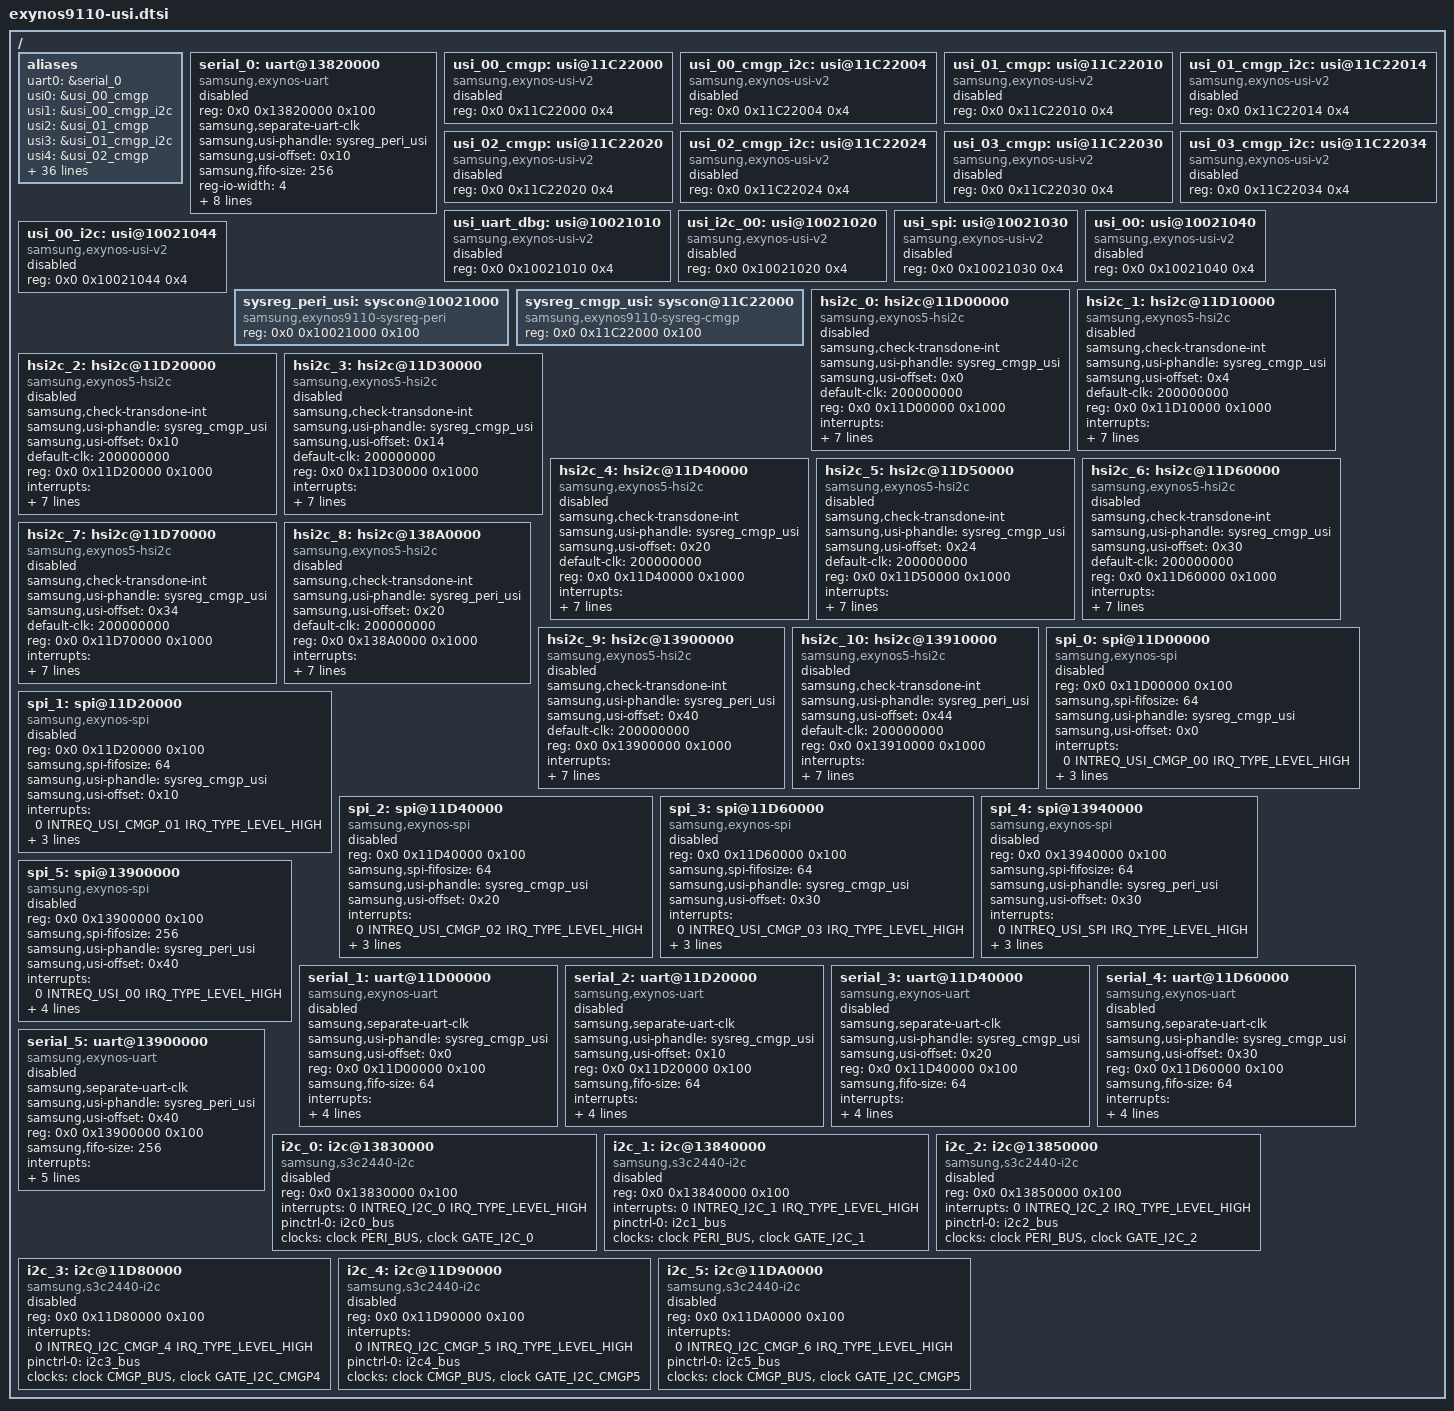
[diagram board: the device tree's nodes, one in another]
/*
 * Samsung's Exynos9110 SoC USI device tree source
 *
 * Copyright (c) 2020 Samsung Electronics Co., Ltd.
 *		http://www.samsung.com
 *
 * Samsung's Exynos9110 SoC USI channels are listed as device
 * tree nodes are listed in this file.
 *
 * This program is free software; you can redistribute it and/or modify
 * it under the terms of the GNU General Public License version 2 as
 * published by the Free Software Foundation.
*/

/ {
	aliases {
		uart0 = &serial_0;
		usi0 = &usi_00_cmgp;
		usi1 = &usi_00_cmgp_i2c;
		usi2 = &usi_01_cmgp;
		usi3 = &usi_01_cmgp_i2c;
		usi4 = &usi_02_cmgp;
		usi5 = &usi_02_cmgp_i2c;
		usi6 = &usi_03_cmgp;
		usi7 = &usi_03_cmgp_i2c;
		usi8 = &usi_uart_dbg;
		usi9 = &usi_i2c_00;
		usi10 = &usi_spi;
		usi11 = &usi_00;
		usi12 = &usi_00_i2c;
		hsi2c0 = &hsi2c_0;
		hsi2c1 = &hsi2c_1;
		hsi2c2 = &hsi2c_2;
		hsi2c3 = &hsi2c_3;
		hsi2c4 = &hsi2c_4;
		hsi2c5 = &hsi2c_5;
		hsi2c6 = &hsi2c_6;
		hsi2c7 = &hsi2c_7;
		hsi2c8 = &hsi2c_8;
		hsi2c9 = &hsi2c_9;
		hsi2c10 = &hsi2c_10;
		spi0 = &spi_0;
		spi1 = &spi_1;
		spi2 = &spi_2;
		spi3 = &spi_3;
		spi4 = &spi_4;
		spi5 = &spi_5;
		uart1 = &serial_1;
		uart2 = &serial_2;
		uart3 = &serial_3;
		uart4 = &serial_4;
		uart5 = &serial_5;
		i2c0 = &i2c_0;
		i2c1 = &i2c_1;
		i2c2 = &i2c_2;
		i2c3 = &i2c_3;
		i2c4 = &i2c_4;
		i2c5 = &i2c_5;
	};

	serial_0: uart@13820000 {
		compatible = "samsung,exynos-uart";
		reg = <0x0 0x13820000 0x100>;
		samsung,separate-uart-clk;
		samsung,usi-phandle = <&sysreg_peri_usi>;
		samsung,usi-offset = <0x10>;
		samsung,fifo-size = <256>;
		reg-io-width = <4>;
		interrupts = <0 INTREQ_USI_UART IRQ_TYPE_LEVEL_HIGH>;
		pinctrl-names = "default";
		pinctrl-0 = <&uart0_bus_single>; /* or _bus_dual */
		clocks = <&clock GATE_USI_UART>, <&clock PERI_UART>;
		clock-names = "gate_uart_clk0", "ipclk_uart0";
		samsung,usi-serial-v2;
		samsung,dbg-uart-ch;
		samsung,dbg-uart-baud = <115200>;
		samsung,dbg-word-len = <8>;
		status = "disabled";
	};

	/* USI_00_CMGP */
	usi_00_cmgp: usi@11C22000 {
		compatible = "samsung,exynos-usi-v2";
		reg = <0x0 0x11C22000 0x4>;
		/*	usi_mode_v2 = "i2c" or "spi" or "uart"	*/
		status = "disabled";
	};

	/* USI_00_CMGP_I2C */
	usi_00_cmgp_i2c: usi@11C22004 {
		compatible = "samsung,exynos-usi-v2";
		reg = <0x0 0x11C22004 0x4>;
		/*	usi_mode_v2 = "i2c" */
		status = "disabled";
	};

	/* USI_01_CMGP */
	usi_01_cmgp: usi@11C22010 {
		compatible = "samsung,exynos-usi-v2";
		reg = <0x0 0x11C22010 0x4>;
		/*	usi_mode_v2 = "i2c" or "spi" or "uart"	*/
		status = "disabled";
	};

	/* USI_01_CMGP_I2C */
	usi_01_cmgp_i2c: usi@11C22014 {
		compatible = "samsung,exynos-usi-v2";
		reg = <0x0 0x11C22014 0x4>;
		/*	usi_mode_v2 = "i2c" */
		status = "disabled";
	};

	/* USI_02_CMGP */
	usi_02_cmgp: usi@11C22020 {
		compatible = "samsung,exynos-usi-v2";
		reg = <0x0 0x11C22020 0x4>;
		/*	usi_mode_v2 = "i2c" or "spi" or "uart"	*/
		status = "disabled";
	};

	/* USI_02_CMGP_I2C */
	usi_02_cmgp_i2c: usi@11C22024 {
		compatible = "samsung,exynos-usi-v2";
		reg = <0x0 0x11C22024 0x4>;
		/*	usi_mode_v2 = "i2c" */
		status = "disabled";
	};

	/* USI_03_CMGP */
	usi_03_cmgp: usi@11C22030 {
		compatible = "samsung,exynos-usi-v2";
		reg = <0x0 0x11C22030 0x4>;
		/*	usi_mode_v2 = "i2c" or "spi" or "uart"	*/
		status = "disabled";
	};

	/* USI_03_CMGP_I2C */
	usi_03_cmgp_i2c: usi@11C22034 {
		compatible = "samsung,exynos-usi-v2";
		reg = <0x0 0x11C22034 0x4>;
		/*	usi_mode_v2 = "i2c" */
		status = "disabled";
	};

	/* USI_UART_DBG */
	usi_uart_dbg: usi@10021010 {
		compatible = "samsung,exynos-usi-v2";
		reg = <0x0 0x10021010 0x4>;
		/*	usi_mode_v2 = "i2c" */
		status = "disabled";
	};

	/* USI_I2C_00 */
	usi_i2c_00: usi@10021020 {
		compatible = "samsung,exynos-usi-v2";
		reg = <0x0 0x10021020 0x4>;
		/*	usi_mode_v2 = "i2c" */
		status = "disabled";
	};

	/* USI_SPI */
	usi_spi: usi@10021030 {
		compatible = "samsung,exynos-usi-v2";
		reg = <0x0 0x10021030 0x4>;
		/*	usi_mode_v2 = "i2c" */
		status = "disabled";
	};

	/* USI_00 */
	usi_00: usi@10021040 {
		compatible = "samsung,exynos-usi-v2";
		reg = <0x0 0x10021040 0x4>;
		/*	usi_mode_v2 = "i2c" */
		status = "disabled";
	};

	/* USI_00_I2C */
	usi_00_i2c: usi@10021044 {
		compatible = "samsung,exynos-usi-v2";
		reg = <0x0 0x10021044 0x4>;
		/*	usi_mode_v2 = "i2c" */
		status = "disabled";
	};

	/* USI_SW_CONF for PERI USI*/
	sysreg_peri_usi: syscon@10021000 {
		compatible = "samsung,exynos9110-sysreg-peri", "syscon";
		reg = <0x0 0x10021000 0x100>;
	};

	/* USI_SW_CONF for CMGP USI*/
	sysreg_cmgp_usi: syscon@11C22000 {
		compatible = "samsung,exynos9110-sysreg-cmgp", "syscon";
		reg = <0x0 0x11C22000 0x100>;
	};

	/* USI_00_CMGP */
	hsi2c_0: hsi2c@11D00000 {
		compatible = "samsung,exynos5-hsi2c";
		samsung,check-transdone-int;
		samsung,usi-phandle = <&sysreg_cmgp_usi>;
		samsung,usi-offset = <0x0>;
		default-clk = <200000000>;
		reg = <0x0 0x11D00000 0x1000>;
		interrupts = <0 INTREQ_USI_CMGP_00 IRQ_TYPE_LEVEL_HIGH>;
		#address-cells = <1>;
		#size-cells = <0>;
		pinctrl-names = "default";
		pinctrl-0 = <&hsi2c0_bus>;
		clocks = <&clock CMGP_USI0>, <&clock GATE_USI_CMGP0>;
		clock-names = "ipclk_hsi2c", "gate_hsi2c_clk";
		samsung,scl-clk-stretching;
		samsung,usi-i2c-v2;
		gpio_scl= <&gpm0 0 0x1>;
		gpio_sda= <&gpm1 0 0x1>;
		status = "disabled";
	};

	/* USI_00_CMGP_I2C */
	hsi2c_1: hsi2c@11D10000 {
		compatible = "samsung,exynos5-hsi2c";
		samsung,check-transdone-int;
		samsung,usi-phandle = <&sysreg_cmgp_usi>;
		samsung,usi-offset = <0x4>;
		default-clk = <200000000>;
		reg = <0x0 0x11D10000 0x1000>;
		interrupts = <0 INTREQ_USI_CMGP_00_I2C IRQ_TYPE_LEVEL_HIGH>;
		#address-cells = <1>;
		#size-cells = <0>;
		pinctrl-names = "default";
		pinctrl-0 = <&hsi2c1_bus>;
		clocks = <&clock CMGP_I2C0>, <&clock GATE_I2C_CMGP0>;
		clock-names = "ipclk_hsi2c", "gate_hsi2c_clk";
		samsung,scl-clk-stretching;
		samsung,usi-i2c-v2;
		gpio_scl= <&gpm2 0 0x1>;
		gpio_sda= <&gpm3 0 0x1>;
		status = "disabled";
	};

	/* USI_01_CMGP */
	hsi2c_2: hsi2c@11D20000 {
		compatible = "samsung,exynos5-hsi2c";
		samsung,check-transdone-int;
		samsung,usi-phandle = <&sysreg_cmgp_usi>;
		samsung,usi-offset = <0x10>;
		default-clk = <200000000>;
		reg = <0x0 0x11D20000 0x1000>;
		interrupts = <0 INTREQ_USI_CMGP_01 IRQ_TYPE_LEVEL_HIGH>;
		#address-cells = <1>;
		#size-cells = <0>;
		pinctrl-names = "default";
		pinctrl-0 = <&hsi2c2_bus>;
		clocks = <&clock CMGP_USI1>, <&clock GATE_USI_CMGP1>;
		clock-names = "ipclk_hsi2c", "gate_hsi2c_clk";
		samsung,scl-clk-stretching;
		samsung,usi-i2c-v2;
		gpio_scl= <&gpm4 0 0x1>;
		gpio_sda= <&gpm5 0 0x1>;
		status = "disabled";
	};

	/* USI_01_CMGP_I2C */
	hsi2c_3: hsi2c@11D30000 {
		compatible = "samsung,exynos5-hsi2c";
		samsung,check-transdone-int;
		samsung,usi-phandle = <&sysreg_cmgp_usi>;
		samsung,usi-offset = <0x14>;
		default-clk = <200000000>;
		reg = <0x0 0x11D30000 0x1000>;
		interrupts = <0 INTREQ_USI_CMGP_01_I2C IRQ_TYPE_LEVEL_HIGH>;
		#address-cells = <1>;
		#size-cells = <0>;
		pinctrl-names = "default";
		pinctrl-0 = <&hsi2c3_bus>;
		clocks = <&clock CMGP_I2C1>, <&clock GATE_I2C_CMGP1>;
		clock-names = "ipclk_hsi2c", "gate_hsi2c_clk";
		samsung,scl-clk-stretching;
		samsung,usi-i2c-v2;
		gpio_scl= <&gpm6 0 0x1>;
		gpio_sda= <&gpm7 0 0x1>;
		status = "disabled";
	};

	/* USI_02_CMGP */
	hsi2c_4: hsi2c@11D40000 {
		compatible = "samsung,exynos5-hsi2c";
		samsung,check-transdone-int;
		samsung,usi-phandle = <&sysreg_cmgp_usi>;
		samsung,usi-offset = <0x20>;
		default-clk = <200000000>;
		reg = <0x0 0x11D40000 0x1000>;
		interrupts = <0 INTREQ_USI_CMGP_02 IRQ_TYPE_LEVEL_HIGH>;
		#address-cells = <1>;
		#size-cells = <0>;
		pinctrl-names = "default";
		pinctrl-0 = <&hsi2c4_bus>;
		clocks = <&clock CMGP_USI2>, <&clock GATE_USI_CMGP2>;
		clock-names = "ipclk_hsi2c", "gate_hsi2c_clk";
		samsung,scl-clk-stretching;
		samsung,usi-i2c-v2;
		gpio_scl= <&gpm8 0 0x1>;
		gpio_sda= <&gpm9 0 0x1>;
		status = "disabled";
	};

	/* USI_02_CMGP_I2C */
	hsi2c_5: hsi2c@11D50000 {
		compatible = "samsung,exynos5-hsi2c";
		samsung,check-transdone-int;
		samsung,usi-phandle = <&sysreg_cmgp_usi>;
		samsung,usi-offset = <0x24>;
		default-clk = <200000000>;
		reg = <0x0 0x11D50000 0x1000>;
		interrupts = <0 INTREQ_USI_CMGP_02_I2C IRQ_TYPE_LEVEL_HIGH>;
		#address-cells = <1>;
		#size-cells = <0>;
		pinctrl-names = "default";
		pinctrl-0 = <&hsi2c5_bus>;
		clocks = <&clock CMGP_I2C2>, <&clock GATE_I2C_CMGP2>;
		clock-names = "ipclk_hsi2c", "gate_hsi2c_clk";
		samsung,scl-clk-stretching;
		samsung,usi-i2c-v2;
		gpio_scl= <&gpm10 0 0x1>;
		gpio_sda= <&gpm11 0 0x1>;
		status = "disabled";
	};

	/* USI_03_CMGP */
	hsi2c_6: hsi2c@11D60000 {
		compatible = "samsung,exynos5-hsi2c";
		samsung,check-transdone-int;
		samsung,usi-phandle = <&sysreg_cmgp_usi>;
		samsung,usi-offset = <0x30>;
		default-clk = <200000000>;
		reg = <0x0 0x11D60000 0x1000>;
		interrupts = <0 INTREQ_USI_CMGP_03 IRQ_TYPE_LEVEL_HIGH>;
		#address-cells = <1>;
		#size-cells = <0>;
		pinctrl-names = "default";
		pinctrl-0 = <&hsi2c6_bus>;
		clocks = <&clock CMGP_USI3>, <&clock GATE_USI_CMGP3>;
		clock-names = "ipclk_hsi2c", "gate_hsi2c_clk";
		samsung,scl-clk-stretching;
		samsung,usi-i2c-v2;
		gpio_scl= <&gpm12 0 0x1>;
		gpio_sda= <&gpm13 1 0x1>;
		status = "disabled";
	};

	/* USI_03_CMGP_I2C */
	hsi2c_7: hsi2c@11D70000 {
		compatible = "samsung,exynos5-hsi2c";
		samsung,check-transdone-int;
		samsung,usi-phandle = <&sysreg_cmgp_usi>;
		samsung,usi-offset = <0x34>;
		default-clk = <200000000>;
		reg = <0x0 0x11D70000 0x1000>;
		interrupts = <0 INTREQ_USI_CMGP_03_I2C IRQ_TYPE_LEVEL_HIGH>;
		#address-cells = <1>;
		#size-cells = <0>;
		pinctrl-names = "default";
		pinctrl-0 = <&hsi2c7_bus>;
		clocks = <&clock CMGP_I2C3>, <&clock GATE_I2C_CMGP3>;
		clock-names = "ipclk_hsi2c", "gate_hsi2c_clk";
		samsung,scl-clk-stretching;
		samsung,usi-i2c-v2;
		gpio_scl= <&gpm14 0 0x1>;
		gpio_sda= <&gpm15 1 0x1>;
		status = "disabled";
	};

	/* USI_I2C_00 */
	hsi2c_8: hsi2c@138A0000 {
		compatible = "samsung,exynos5-hsi2c";
		samsung,check-transdone-int;
		samsung,usi-phandle = <&sysreg_peri_usi>;
		samsung,usi-offset = <0x20>;
		default-clk = <200000000>;
		reg = <0x0 0x138A0000 0x1000>;
		interrupts = <0 INTREQ_USI_I2C_00 IRQ_TYPE_LEVEL_HIGH>;
		#address-cells = <1>;
		#size-cells = <0>;
		pinctrl-names = "default";
		pinctrl-0 = <&hsi2c8_bus>;
		clocks = <&clock PERI_HSI2C>, <&clock GATE_USI_I2C_0>;
		clock-names = "ipclk_hsi2c", "gate_hsi2c_clk";
		samsung,scl-clk-stretching;
		samsung,usi-i2c-v2;
		gpio_scl= <&gpp3 0 0x1>;
		gpio_sda= <&gpp3 1 0x1>;
		status = "disabled";
	};

	/* USI_00 */
	hsi2c_9: hsi2c@13900000 {
		compatible = "samsung,exynos5-hsi2c";
		samsung,check-transdone-int;
		samsung,usi-phandle = <&sysreg_peri_usi>;
		samsung,usi-offset = <0x40>;
		default-clk = <200000000>;
		reg = <0x0 0x13900000 0x1000>;
		interrupts = <0 INTREQ_USI_00 IRQ_TYPE_LEVEL_HIGH>;
		#address-cells = <1>;
		#size-cells = <0>;
		pinctrl-names = "default";
		pinctrl-0 = <&hsi2c9_bus>;
		clocks = <&clock PERI_BUS>, <&clock GATE_I2C_0>;
		clock-names = "ipclk_hsi2c", "gate_hsi2c_clk";
		samsung,scl-clk-stretching;
		samsung,usi-i2c-v2;
		gpio_scl= <&gpc0 0 0x1>;
		gpio_sda= <&gpc0 1 0x1>;
		status = "disabled";
	};

	/* USI_00_I2C */
	hsi2c_10: hsi2c@13910000 {
		compatible = "samsung,exynos5-hsi2c";
		samsung,check-transdone-int;
		samsung,usi-phandle = <&sysreg_peri_usi>;
		samsung,usi-offset = <0x44>;
		default-clk = <200000000>;
		reg = <0x0 0x13910000 0x1000>;
		interrupts = <0 INTREQ_USI_00_I2C IRQ_TYPE_LEVEL_HIGH>;
		#address-cells = <1>;
		#size-cells = <0>;
		pinctrl-names = "default";
		pinctrl-0 = <&hsi2c10_bus>;
		clocks = <&clock PERI_BUS>, <&clock GATE_I2C_1>;
		clock-names = "ipclk_hsi2c", "gate_hsi2c_clk";
		samsung,scl-clk-stretching;
		samsung,usi-i2c-v2;
		gpio_scl= <&gpc0 2 0x1>;
		gpio_sda= <&gpc0 3 0x1>;
		status = "disabled";
	};

	/* SPI USI_00_CMGP */
	spi_0: spi@11D00000 {
		compatible = "samsung,exynos-spi";
		reg = <0x0 0x11D00000 0x100>;
		samsung,spi-fifosize = <64>;
		samsung,usi-phandle = <&sysreg_cmgp_usi>;
		samsung,usi-offset = <0x0>;
		interrupts = <0 INTREQ_USI_CMGP_00 IRQ_TYPE_LEVEL_HIGH>;
/*
		dma-mode;
		dmas = <&pdma0 25 &pdma0 24>;
*/
		dma-names = "tx", "rx";
		swap-mode;
		#address-cells = <1>;
		#size-cells = <0>;
		clocks = <&clock GATE_USI_CMGP0>, <&clock CMGP_USI0>;
		clock-names = "gate_spi_clk", "ipclk_spi";
		pinctrl-names = "default";
		pinctrl-0 = <&spi0_bus>;
		status = "disabled";
	};

	/* SPI USI_01_CMGP */
	spi_1: spi@11D20000 {
		compatible = "samsung,exynos-spi";
		reg = <0x0 0x11D20000 0x100>;
		samsung,spi-fifosize = <64>;
		samsung,usi-phandle = <&sysreg_cmgp_usi>;
		samsung,usi-offset = <0x10>;
		interrupts = <0 INTREQ_USI_CMGP_01 IRQ_TYPE_LEVEL_HIGH>;
/*
		dma-mode;
		dmas = <&pdma0 25 &pdma0 24>;
*/
		dma-names = "tx", "rx";
		swap-mode;
		#address-cells = <1>;
		#size-cells = <0>;
		clocks = <&clock GATE_USI_CMGP1>, <&clock CMGP_USI1>;
		clock-names = "gate_spi_clk", "ipclk_spi";
		pinctrl-names = "default";
		pinctrl-0 = <&spi1_bus>;
		status = "disabled";
	};

	/* SPI USI_02_CMGP */
	spi_2: spi@11D40000 {
		compatible = "samsung,exynos-spi";
		reg = <0x0 0x11D40000 0x100>;
		samsung,spi-fifosize = <64>;
		samsung,usi-phandle = <&sysreg_cmgp_usi>;
		samsung,usi-offset = <0x20>;
		interrupts = <0 INTREQ_USI_CMGP_02 IRQ_TYPE_LEVEL_HIGH>;
/*
		dma-mode;
		dmas = <&pdma0 25 &pdma0 24>;
*/
		dma-names = "tx", "rx";
		swap-mode;
		#address-cells = <1>;
		#size-cells = <0>;
		clocks = <&clock GATE_USI_CMGP2>, <&clock CMGP_USI2>;
		clock-names = "gate_spi_clk", "ipclk_spi";
		pinctrl-names = "default";
		pinctrl-0 = <&spi2_bus>;
		status = "disabled";
	};

	/* SPI USI_03_CMGP */
	spi_3: spi@11D60000 {
		compatible = "samsung,exynos-spi";
		reg = <0x0 0x11D60000 0x100>;
		samsung,spi-fifosize = <64>;
		samsung,usi-phandle = <&sysreg_cmgp_usi>;
		samsung,usi-offset = <0x30>;
		interrupts = <0 INTREQ_USI_CMGP_03 IRQ_TYPE_LEVEL_HIGH>;
/*
		dma-mode;
		dmas = <&pdma0 25 &pdma0 24>;
*/
		dma-names = "tx", "rx";
		swap-mode;
		#address-cells = <1>;
		#size-cells = <0>;
		clocks = <&clock GATE_USI_CMGP3>, <&clock CMGP_USI3>;
		clock-names = "gate_spi_clk", "ipclk_spi";
		pinctrl-names = "default";
		pinctrl-0 = <&spi3_bus>;
		status = "disabled";
	};

	/* SPI USI_SPI */
	spi_4: spi@13940000 {
		compatible = "samsung,exynos-spi";
		reg = <0x0 0x13940000 0x100>;
		samsung,spi-fifosize = <64>;
		samsung,usi-phandle = <&sysreg_peri_usi>;
		samsung,usi-offset = <0x30>;
		interrupts = <0 INTREQ_USI_SPI IRQ_TYPE_LEVEL_HIGH>;
/*
		dma-mode;
		dmas = <&pdma0 25 &pdma0 24>;
*/
		dma-names = "tx", "rx";
		swap-mode;
		#address-cells = <1>;
		#size-cells = <0>;
		clocks = <&clock GATE_USI_SPI>, <&clock PERI_SPI>;
		clock-names = "gate_spi_clk", "ipclk_spi";
		pinctrl-names = "default";
		pinctrl-0 = <&spi4_bus>;
		status = "disabled";
	};

	/* SPI USI_00 */
	spi_5: spi@13900000 {
		compatible = "samsung,exynos-spi";
		reg = <0x0 0x13900000 0x100>;
		samsung,spi-fifosize = <256>;
		samsung,usi-phandle = <&sysreg_peri_usi>;
		samsung,usi-offset = <0x40>;
		interrupts = <0 INTREQ_USI_00 IRQ_TYPE_LEVEL_HIGH>;
/*
		dma-mode;
		dmas = <&pdma0 25 &pdma0 24>;
*/
		dma-names = "tx", "rx";
		swap-mode;
		#address-cells = <1>;
		#size-cells = <0>;
		clocks = <&clock GATE_USI00_USI>, <&clock PERI_USI00_USI>;
		clock-names = "gate_spi_clk", "ipclk_spi";
		pinctrl-names = "default";
		pinctrl-0 = <&spi5_bus>;
		status = "disabled";
	};

	/* USI_00_CMGP */
	serial_1: uart@11D00000 {
		compatible = "samsung,exynos-uart";
		samsung,separate-uart-clk;
		samsung,usi-phandle = <&sysreg_cmgp_usi>;
		samsung,usi-offset = <0x0>;
		reg = <0x0 0x11D00000 0x100>;
		samsung,fifo-size = <64>;
		interrupts = <0 INTREQ_USI_CMGP_00 IRQ_TYPE_LEVEL_HIGH>;
		pinctrl-names = "default";
		pinctrl-0 = <&uart1_bus_single>; /* or _bus_dual */
		samsung,usi-serial-v2;
		clocks = <&clock GATE_USI_CMGP0>, <&clock CMGP_USI0>;
		clock-names = "gate_uart_clk1", "ipclk_uart1";
		status = "disabled";
	};

	/* USI_01_CMGP */
	serial_2: uart@11D20000 {
		compatible = "samsung,exynos-uart";
		samsung,separate-uart-clk;
		samsung,usi-phandle = <&sysreg_cmgp_usi>;
		samsung,usi-offset = <0x10>;
		reg = <0x0 0x11D20000 0x100>;
		samsung,fifo-size = <64>;
		interrupts = <0 INTREQ_USI_CMGP_01 IRQ_TYPE_LEVEL_HIGH>;
		pinctrl-names = "default";
		pinctrl-0 = <&uart2_bus_single>; /* or _bus_dual */
		samsung,usi-serial-v2;
		clocks = <&clock GATE_USI_CMGP1>, <&clock CMGP_USI1>;
		clock-names = "gate_uart_clk2", "ipclk_uart2";
		status = "disabled";
	};

	/* USI_02_CMGP */
	serial_3: uart@11D40000 {
		compatible = "samsung,exynos-uart";
		samsung,separate-uart-clk;
		samsung,usi-phandle = <&sysreg_cmgp_usi>;
		samsung,usi-offset = <0x20>;
		reg = <0x0 0x11D40000 0x100>;
		samsung,fifo-size = <64>;
		interrupts = <0 INTREQ_USI_CMGP_02 IRQ_TYPE_LEVEL_HIGH>;
		pinctrl-names = "default";
		pinctrl-0 = <&uart3_bus_single>; /* or _bus_dual */
		samsung,usi-serial-v2;
		clocks = <&clock GATE_USI_CMGP2>, <&clock CMGP_USI2>;
		clock-names = "gate_uart_clk3", "ipclk_uart3";
		status = "disabled";
	};

	/* USI_03_CMGP */
	serial_4: uart@11D60000 {
		compatible = "samsung,exynos-uart";
		samsung,separate-uart-clk;
		samsung,usi-phandle = <&sysreg_cmgp_usi>;
		samsung,usi-offset = <0x30>;
		reg = <0x0 0x11D60000 0x100>;
		samsung,fifo-size = <64>;
		interrupts = <0 INTREQ_USI_CMGP_03 IRQ_TYPE_LEVEL_HIGH>;
		pinctrl-names = "default";
		pinctrl-0 = <&uart4_bus_single>; /* or _bus_dual */
		samsung,usi-serial-v2;
		clocks = <&clock GATE_USI_CMGP3>, <&clock CMGP_USI3>;
		clock-names = "gate_uart_clk4", "ipclk_uart4";
		status = "disabled";
	};

	/* USI_00 */
	serial_5: uart@13900000 {
		compatible = "samsung,exynos-uart";
		samsung,separate-uart-clk;
		samsung,usi-phandle = <&sysreg_peri_usi>;
		samsung,usi-offset = <0x40>;
		reg = <0x0 0x13900000 0x100>;
		samsung,fifo-size = <256>;
		interrupts = <0 INTREQ_USI_00 IRQ_TYPE_LEVEL_HIGH>;
		pinctrl-names = "default";
		pinctrl-0 = <&uart5_bus_single>; /* or _bus_dual */
		samsung,usi-serial-v2;
		clocks = <&clock GATE_USI00_USI>, <&clock PERI_USI00_USI>;
		clock-names = "gate_uart_clk5", "ipclk_uart5";
		status = "disabled";
	};

	/* I2C_0 */
	i2c_0: i2c@13830000 {
		compatible = "samsung,s3c2440-i2c";
		reg = <0x0 0x13830000 0x100>;
		interrupts = <0 INTREQ_I2C_0 IRQ_TYPE_LEVEL_HIGH>;
		#address-cells = <1>;
		#size-cells = <0>;
		pinctrl-names = "default";
		pinctrl-0 = <&i2c0_bus>;
		clocks = <&clock PERI_BUS>, <&clock GATE_I2C_0>;
		clock-names = "rate_i2c", "gate_i2c";
		status = "disabled";
	};

	/* I2C_1 */
	i2c_1: i2c@13840000 {
		compatible = "samsung,s3c2440-i2c";
		reg = <0x0 0x13840000 0x100>;
		interrupts = <0 INTREQ_I2C_1 IRQ_TYPE_LEVEL_HIGH>;
		#address-cells = <1>;
		#size-cells = <0>;
		pinctrl-names = "default";
		pinctrl-0 = <&i2c1_bus>;
		clocks = <&clock PERI_BUS>, <&clock GATE_I2C_1>;
		clock-names = "rate_i2c", "gate_i2c";
		status = "disabled";
	};

	/* I2C_2 */
	i2c_2: i2c@13850000 {
		compatible = "samsung,s3c2440-i2c";
		reg = <0x0 0x13850000 0x100>;
		interrupts = <0 INTREQ_I2C_2 IRQ_TYPE_LEVEL_HIGH>;
		#address-cells = <1>;
		#size-cells = <0>;
		pinctrl-names = "default";
		pinctrl-0 = <&i2c2_bus>;
		clocks = <&clock PERI_BUS>, <&clock GATE_I2C_2>;
		clock-names = "rate_i2c", "gate_i2c";
		status = "disabled";
	};

	/* I2C_CMGP_4 */
	i2c_3: i2c@11D80000 {
		compatible = "samsung,s3c2440-i2c";
		reg = <0x0 0x11D80000 0x100>;
		interrupts = <0 INTREQ_I2C_CMGP_4 IRQ_TYPE_LEVEL_HIGH>;
		#address-cells = <1>;
		#size-cells = <0>;
		pinctrl-names = "default";
		pinctrl-0 = <&i2c3_bus>;
		clocks = <&clock CMGP_BUS>, <&clock GATE_I2C_CMGP4>;
		clock-names = "rate_i2c", "gate_i2c";
		status = "disabled";
	};

	/* I2C_CMGP_5 */
	i2c_4: i2c@11D90000 {
		compatible = "samsung,s3c2440-i2c";
		reg = <0x0 0x11D90000 0x100>;
		interrupts = <0 INTREQ_I2C_CMGP_5 IRQ_TYPE_LEVEL_HIGH>;
		#address-cells = <1>;
		#size-cells = <0>;
		pinctrl-names = "default";
		pinctrl-0 = <&i2c4_bus>;
		clocks = <&clock CMGP_BUS>, <&clock GATE_I2C_CMGP5>;
		clock-names = "rate_i2c", "gate_i2c";
		status = "disabled";
	};

	/* I2C_CMGP_6 */
	i2c_5: i2c@11DA0000 {
		compatible = "samsung,s3c2440-i2c";
		reg = <0x0 0x11DA0000 0x100>;
		interrupts = <0 INTREQ_I2C_CMGP_6 IRQ_TYPE_LEVEL_HIGH>;
		#address-cells = <1>;
		#size-cells = <0>;
		pinctrl-names = "default";
		pinctrl-0 = <&i2c5_bus>;
		clocks = <&clock CMGP_BUS>, <&clock GATE_I2C_CMGP5>;
		clock-names = "rate_i2c", "gate_i2c";
		status = "disabled";
	};

};
